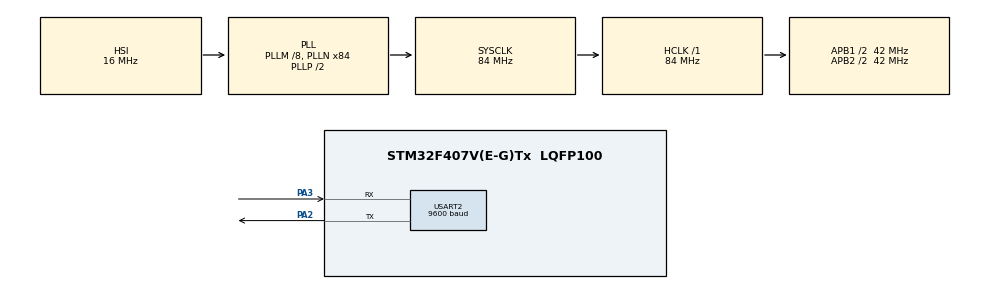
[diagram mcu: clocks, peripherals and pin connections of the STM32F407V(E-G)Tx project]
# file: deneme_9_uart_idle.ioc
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Dma.Request0=USART2_RX
Dma.Request1=USART2_TX
Dma.USART2_RX.0.Direction=DMA_PERIPH_TO_MEMORY
Dma.USART2_RX.0.FIFOMode=DMA_FIFOMODE_DISABLE
Dma.USART2_RX.0.Instance=DMA1_Stream5
Dma.USART2_RX.0.MemDataAlignment=DMA_MDATAALIGN_BYTE
Dma.USART2_RX.0.MemInc=DMA_MINC_ENABLE
Dma.USART2_RX.0.Mode=DMA_NORMAL
Dma.USART2_RX.0.PeriphDataAlignment=DMA_PDATAALIGN_BYTE
Dma.USART2_RX.0.PeriphInc=DMA_PINC_DISABLE
Dma.USART2_RX.0.Priority=DMA_PRIORITY_LOW
Dma.USART2_TX.1.Direction=DMA_MEMORY_TO_PERIPH
Dma.USART2_TX.1.FIFOMode=DMA_FIFOMODE_DISABLE
Dma.USART2_TX.1.Instance=DMA1_Stream6
Dma.USART2_TX.1.MemDataAlignment=DMA_MDATAALIGN_BYTE
Dma.USART2_TX.1.MemInc=DMA_MINC_ENABLE
Dma.USART2_TX.1.Mode=DMA_NORMAL
Dma.USART2_TX.1.PeriphDataAlignment=DMA_PDATAALIGN_BYTE
Dma.USART2_TX.1.PeriphInc=DMA_PINC_DISABLE
Dma.USART2_TX.1.Priority=DMA_PRIORITY_LOW
Mcu.Family=STM32F4
Mcu.Name=STM32F407V(E-G)Tx
Mcu.Package=LQFP100
NVIC.DMA1_Stream5_IRQn=true\:0\:0\:false\:false\:true\:false\:true
NVIC.DMA1_Stream6_IRQn=true\:0\:0\:false\:false\:true\:false\:true
NVIC.PriorityGroup=NVIC_PRIORITYGROUP_4
NVIC.RCC_IRQn=true\:0\:0\:false\:false\:true\:true\:false
NVIC.USART2_IRQn=true\:0\:0\:false\:false\:true\:true\:true
PA2.Mode=Asynchronous
PA2.Signal=USART2_TX
PA3.Mode=Asynchronous
PA3.Signal=USART2_RX
PC14-OSC32_IN.Mode=LSE-External-Oscillator
PC14-OSC32_IN.Signal=RCC_OSC32_IN
PC15-OSC32_OUT.Mode=LSE-External-Oscillator
PC15-OSC32_OUT.Signal=RCC_OSC32_OUT
PH0-OSC_IN.Mode=HSE-External-Oscillator
PH0-OSC_IN.Signal=RCC_OSC_IN
PH1-OSC_OUT.Mode=HSE-External-Oscillator
PH1-OSC_OUT.Signal=RCC_OSC_OUT
ProjectManager.HeapSize=0x200
ProjectManager.StackSize=0x400
ProjectManager.TargetToolchain=STM32CubeIDE
RCC.48MHZClocksFreq_Value=42000000
RCC.AHBFreq_Value=84000000
RCC.APB1CLKDivider=RCC_HCLK_DIV2
RCC.APB1Freq_Value=42000000
RCC.APB1TimFreq_Value=84000000
RCC.APB2CLKDivider=RCC_HCLK_DIV2
RCC.APB2Freq_Value=42000000
RCC.APB2TimFreq_Value=84000000
RCC.CortexFreq_Value=84000000
RCC.HCLKFreq_Value=84000000
RCC.HSE_VALUE=25000000
RCC.HSI_VALUE=16000000
RCC.PLLM=8
RCC.PLLN=84
RCC.SYSCLKFreq_VALUE=84000000
RCC.SYSCLKSource=RCC_SYSCLKSOURCE_PLLCLK
RCC.VCOOutputFreq_Value=168000000
USART2.BaudRate=9600
USART2.VirtualMode=VM_ASYNC
board=custom

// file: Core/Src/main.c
/* USER CODE BEGIN Header */
/**
  ******************************************************************************
  * @file           : main.c
  * @brief          : Main program body
  ******************************************************************************
  * @attention
  *
  * <h2><center>&copy; Copyright (c) 2023 STMicroelectronics.
  * All rights reserved.</center></h2>
  *
  * This software component is licensed by ST under BSD 3-Clause license,
  * the "License"; You may not use this file except in compliance with the
  * License. You may obtain a copy of the License at:
  *                        opensource.org/licenses/BSD-3-Clause
  *
  ******************************************************************************
  */
/* USER CODE END Header */
#include "main.h"
#include "dma.h"
#include "usart.h"
#include "gpio.h"

/* USER CODE BEGIN Includes */
#include "string.h"
/* USER CODE END Includes */

/* USER CODE BEGIN PM */
extern

/* USER CODE END PM */

/* USER CODE BEGIN PV */
#define RxBuf_SIZE   10
#define Mainbuf_SIZE 20

#define RxBufferSize 50
uint8_t RxBufferDizi[RxBufferSize];

uint8_t RxBuf[RxBuf_SIZE];
uint8_t MainBuf[Mainbuf_SIZE];

UART_HandleTypeDef huart2;
DMA_HandleTypeDef hdma_usart2_tx;
DMA_HandleTypeDef hdma_usart2_rx;

/* USER CODE END PV */

void SystemClock_Config(void);

/* USER CODE BEGIN 0 */
void HAL_UARTEx_RxEventCallback(UART_HandleTypeDef *huart, uint16_t Size)
{
	if(huart->Instance == USART2)
	{
		HAL_UARTEx_ReceiveToIdle_DMA(&huart2, RxBufferDizi, RxBufferSize);
		__HAL_DMA_DISABLE_IT(&hdma_usart2_rx, DMA_IT_HT);
	}
}

/* USER CODE END 0 */

int main(void)
{

  /* MCU Configuration--------------------------------------------------------*/

  /* Reset of all peripherals, Initializes the Flash interface and the Systick. */
  HAL_Init();

  /* Configure the system clock */
  SystemClock_Config();

  /* Initialize all configured peripherals */
  MX_GPIO_Init();
  MX_USART2_UART_Init();
  MX_DMA_Init();
  /* USER CODE BEGIN 2 */

  HAL_UARTEx_ReceiveToIdle_DMA(&huart2, RxBufferDizi, RxBufferSize);
  __HAL_DMA_DISABLE_IT(&hdma_usart2_rx, DMA_IT_HT);

  /* USER CODE END 2 */

  /* Infinite loop */
  while (1)
  {

  }
}

void SystemClock_Config(void)
{
  RCC_OscInitTypeDef RCC_OscInitStruct = {0};
  RCC_ClkInitTypeDef RCC_ClkInitStruct = {0};

  /** Configure the main internal regulator output voltage
  */
  __HAL_RCC_PWR_CLK_ENABLE();
  __HAL_PWR_VOLTAGESCALING_CONFIG(PWR_REGULATOR_VOLTAGE_SCALE1);
  /** Initializes the RCC Oscillators according to the specified parameters
  * in the RCC_OscInitTypeDef structure.
  */
  RCC_OscInitStruct.OscillatorType = RCC_OSCILLATORTYPE_HSI;
  RCC_OscInitStruct.HSIState = RCC_HSI_ON;
  RCC_OscInitStruct.HSICalibrationValue = RCC_HSICALIBRATION_DEFAULT;
  RCC_OscInitStruct.PLL.PLLState = RCC_PLL_ON;
  RCC_OscInitStruct.PLL.PLLSource = RCC_PLLSOURCE_HSI;
  RCC_OscInitStruct.PLL.PLLM = 8;
  RCC_OscInitStruct.PLL.PLLN = 84;
  RCC_OscInitStruct.PLL.PLLP = RCC_PLLP_DIV2;
  RCC_OscInitStruct.PLL.PLLQ = 4;
  if (HAL_RCC_OscConfig(&RCC_OscInitStruct) != HAL_OK)
  {
    Error_Handler();
  }
  /** Initializes the CPU, AHB and APB buses clocks
  */
  RCC_ClkInitStruct.ClockType = RCC_CLOCKTYPE_HCLK|RCC_CLOCKTYPE_SYSCLK
                              |RCC_CLOCKTYPE_PCLK1|RCC_CLOCKTYPE_PCLK2;
  RCC_ClkInitStruct.SYSCLKSource = RCC_SYSCLKSOURCE_PLLCLK;
  RCC_ClkInitStruct.AHBCLKDivider = RCC_SYSCLK_DIV1;
  RCC_ClkInitStruct.APB1CLKDivider = RCC_HCLK_DIV2;
  RCC_ClkInitStruct.APB2CLKDivider = RCC_HCLK_DIV2;

  if (HAL_RCC_ClockConfig(&RCC_ClkInitStruct, FLASH_LATENCY_2) != HAL_OK)
  {
    Error_Handler();
  }
}

void Error_Handler(void)
{
  __disable_irq();
  while (1)
  {
  }
}

/************************ (C) COPYRIGHT STMicroelectronics *****END OF FILE****/
